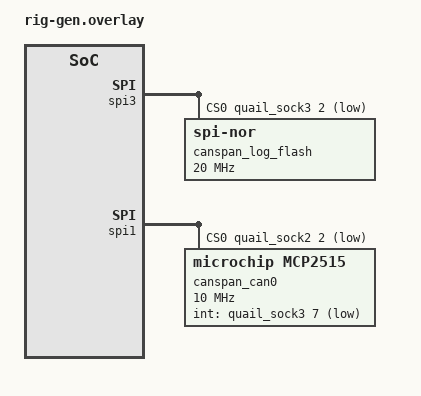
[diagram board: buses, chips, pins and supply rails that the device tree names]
/* generated by rigc — do not edit; the rig file is the source of truth (R3)
 * rig: quail_can_span  board: mikroe_quail/stm32f427xx/rig
 */

&spi3 {
	cs-gpios = <&quail_sock3 2 1 /* ACTIVE_LOW */>;
	canspan_log_flash: log_flash@0 {
		compatible = "jedec,spi-nor";
		spi-max-frequency = <20000000>;
		size = <8388608>;
		reg = <0>;
		status = "okay";
	};
};

&spi1 {
	cs-gpios = <&quail_sock2 2 1 /* ACTIVE_LOW */>;
	canspan_can0: can0@0 {
		compatible = "microchip,mcp2515";
		spi-max-frequency = <10000000>;
		osc-freq = <8000000>;
		reg = <0>;
		int-gpios = <&quail_sock3 7 0x1>;	/* INT */
		status = "okay";
	};
};
